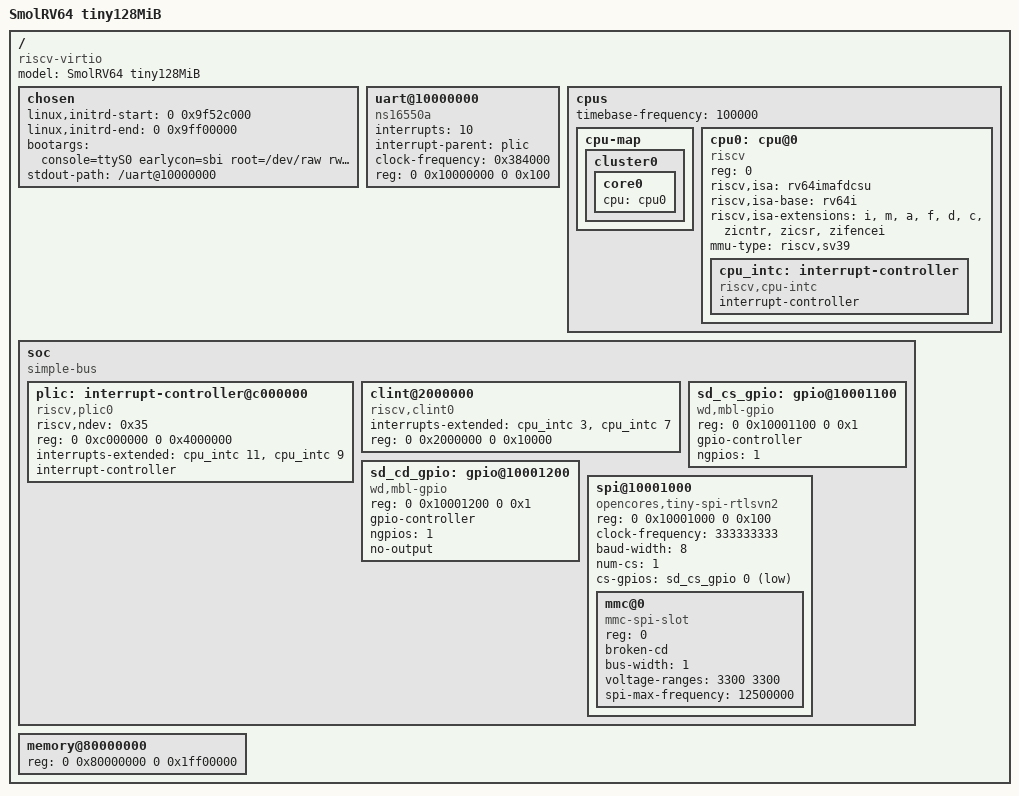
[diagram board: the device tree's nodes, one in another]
/dts-v1/;

/ {
	#address-cells = <2>;
	#size-cells = <2>;
	compatible = "riscv-virtio";
	model = "SmolRV64 tiny128MiB";

	chosen {
		linux,initrd-start = <0 0x9f52c000>;
		linux,initrd-end   = <0 0x9ff00000>;
		bootargs = "console=ttyS0 earlycon=sbi root=/dev/raw rw ignore_loglevel";
		stdout-path = "/uart@10000000";
	};

	uart@10000000 {
		interrupts = <10>;
		interrupt-parent = <&plic>;
		clock-frequency = <0x384000>;
		reg = <0 0x10000000 0 0x100>;
		compatible = "ns16550a";
	};

	cpus {
		#address-cells = <1>;
		#size-cells = <0>;
		timebase-frequency = <100000>; /* 100 kHz */

		cpu-map {

			cluster0 {

				core0 {
					cpu = <&cpu0>;
				};
			};
		};

		cpu0: cpu@0 {
			device_type = "cpu";
			reg = <0>;
			status = "okay";
			compatible = "riscv";
			riscv,isa = "rv64imafdcsu";
			riscv,isa-base = "rv64i";
			riscv,isa-extensions = "i", "m", "a", "f", "d", "c",
				"zicntr", "zicsr", "zifencei";
			mmu-type = "riscv,sv39";

			cpu_intc: interrupt-controller {
				#interrupt-cells = <1>;
				interrupt-controller;
				compatible = "riscv,cpu-intc";
			};
		};
	};

	soc {
		#address-cells = <2>;
		#size-cells = <2>;
		compatible = "simple-bus";
		ranges;

		plic: interrupt-controller@c000000 {
			riscv,ndev = <0x35>;
			reg = <0 0xc000000 0 0x4000000>;
			interrupts-extended = <&cpu_intc 11 &cpu_intc 9>;
			interrupt-controller;
			compatible = "riscv,plic0";
			#interrupt-cells = <1>;
			#address-cells = <0>;
		};

		clint@2000000 {
			interrupts-extended = <&cpu_intc 3 &cpu_intc 7>;
			reg = <0 0x2000000 0 0x10000>;
			compatible = "riscv,clint0";
		};

		sd_cs_gpio: gpio@10001100 {
			compatible = "wd,mbl-gpio";
			reg = <0 0x10001100 0 0x1>;
			reg-names = "dat";
			gpio-controller;
			#gpio-cells = <2>;
			ngpios = <1>;
		};

		sd_cd_gpio: gpio@10001200 {
			compatible = "wd,mbl-gpio";
			reg = <0 0x10001200 0 0x1>;
			reg-names = "dat";
			gpio-controller;
			#gpio-cells = <2>;
			ngpios = <1>;
			no-output;
		};

		spi@10001000 {
			compatible = "opencores,tiny-spi-rtlsvn2";
			reg = <0 0x10001000 0 0x100>;
			clock-frequency = <333333333>;
			baud-width = <8>;
			num-cs = <1>;
			cs-gpios = <&sd_cs_gpio 0 1>; /* GPIO_ACTIVE_LOW */
			#address-cells = <1>;
			#size-cells = <0>;

			mmc@0 {
				compatible = "mmc-spi-slot";
				reg = <0>;
				broken-cd;
				bus-width = <1>;
				voltage-ranges = <3300 3300>;
				spi-max-frequency = <12500000>;
			};
		};
	};

	memory@80000000 {
		device_type = "memory";
		reg = <0 0x80000000 0 0x1ff00000>; // 511 MiB
	};
};
